# ENCODER0_REG_MTX register map
Vendor: Texas Instruments
Peripheral module from a debugger description file (folder J7ES).
Registers are 32-bit, access per field, reset 0x0 unless marked. A register's access mark holds for its fields unless they carry their own. Offsets are as the file gives them; lines under a group give offsets from that group; [hi:lo] are bit positions; {n}, {i} and the like mark numbered series; 'fields as' and 'values as' point back to an identical list; <NAME> marks a mode.

## ENCODER0_REG_MTX
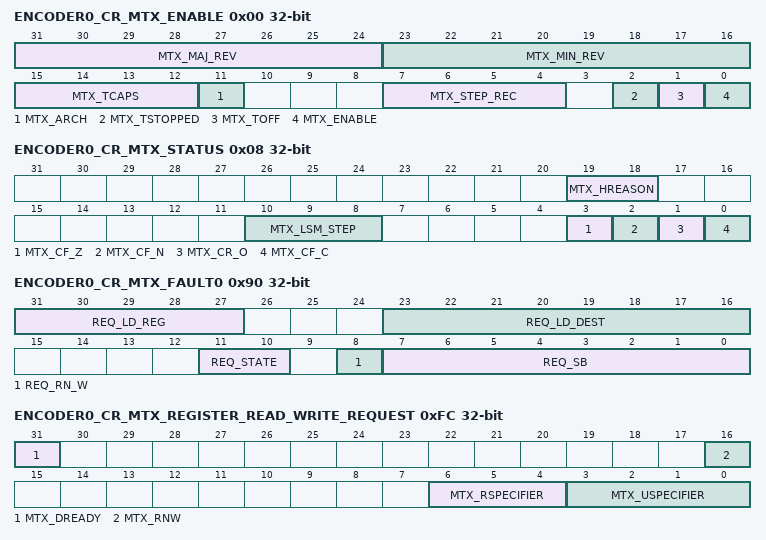
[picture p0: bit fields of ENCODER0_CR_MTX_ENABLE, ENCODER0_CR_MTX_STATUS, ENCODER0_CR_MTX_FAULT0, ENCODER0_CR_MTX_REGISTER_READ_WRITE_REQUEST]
0x00 ENCODER0_CR_MTX_ENABLE
  [31:24] MTX_MAJ_REV rw, [23:16] MTX_MIN_REV rw, [15:12] MTX_TCAPS rw, [11] MTX_ARCH rw, [7:4] MTX_STEP_REC rw, [2] MTX_TSTOPPED rw, [1] MTX_TOFF rw, [0] MTX_ENABLE rw
0x08 ENCODER0_CR_MTX_STATUS
  [19:18] MTX_HREASON rw, [10:8] MTX_LSM_STEP rw, [3] MTX_CF_Z rw, [2] MTX_CF_N rw, [1] MTX_CR_O rw, [0] MTX_CF_C rw
0x80 ENCODER0_CR_MTX_KICK
  [15:0] MTX_KICK rw
0x88 ENCODER0_CR_MTX_KICKI
  [15:0] MTX_KICKI rw
0x90 ENCODER0_CR_MTX_FAULT0
  [31:27] REQ_LD_REG rw, [23:16] REQ_LD_DEST rw, [11:10] REQ_STATE rw, [8] REQ_RN_W rw, [7:0] REQ_SB rw
0xF8 ENCODER0_CR_MTX_REGISTER_READ_WRITE_DATA rw
  [31:0] MTX_RWDATA
0xFC ENCODER0_CR_MTX_REGISTER_READ_WRITE_REQUEST
  [31] MTX_DREADY rw, [16] MTX_RNW rw, [6:4] MTX_RSPECIFIER rw, [3:0] MTX_USPECIFIER rw
0x100 ENCODER0_CR_MTX_RAM_ACCESS_DATA_EXCHANGE rw
  [31:0] MTX_MCMDATAX
0x104 ENCODER0_CR_MTX_RAM_ACCESS_DATA_TRANSFER rw
  [31:0] MTX_MCMDATAT
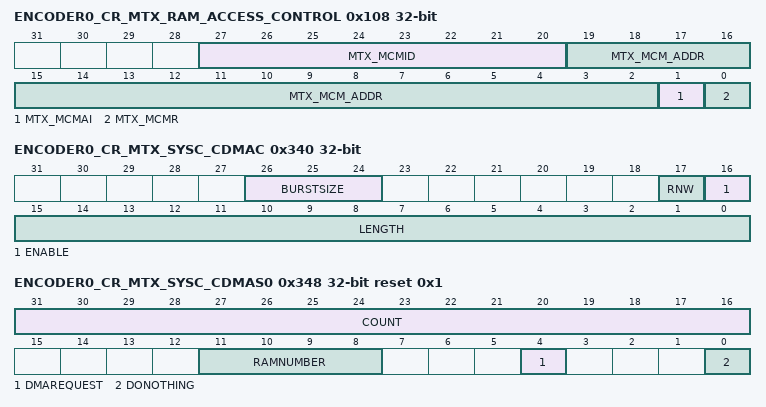
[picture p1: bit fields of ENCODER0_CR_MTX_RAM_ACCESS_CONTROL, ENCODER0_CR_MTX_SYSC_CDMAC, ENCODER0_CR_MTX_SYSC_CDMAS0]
0x108 ENCODER0_CR_MTX_RAM_ACCESS_CONTROL
  [27:20] MTX_MCMID rw, [19:2] MTX_MCM_ADDR rw, [1] MTX_MCMAI rw, [0] MTX_MCMR rw
0x10C ENCODER0_CR_MTX_RAM_ACCESS_STATUS
  [0] MTX_MTX_MCM_STAT rw
0x200 ENCODER0_CR_MTX_SOFT_RESET
  [0] MTX_RESET rw
0x340 ENCODER0_CR_MTX_SYSC_CDMAC
  [26:24] BURSTSIZE rw — This specifies the burst size used for DMA transfers.
  [17] RNW rw — This should be set to '0' to write to the core memories, or '1' to read from the core memories.
  [16] ENABLE rw — Causes a transfer to begin next time the transfer state machine is ready.
  [15:0] LENGTH rw — This specifies the transfer size of the DMA operation in terms of
0x344 ENCODER0_CR_MTX_SYSC_CDMAA
  [25:2] CDMAA_ADDRESS rw — This is the core DMA transfer start address.
0x348 ENCODER0_CR_MTX_SYSC_CDMAS0 ro reset 0x1
  [31:16] COUNT — This is the count of remaining items to be transferred.
  [11:8] RAMNUMBER — This indicates the current RAM number that a DMA transfer is targeting.
  [4] DMAREQUEST — This is a duplicate of the DMA request hardware line from this block to the DMA controller and may be needed if data transfer is from a host processor rather than the DMA controller.
  [0] DONOTHING — Transfer State == 'do_nothing'.
0x34C ENCODER0_CR_MTX_SYSC_CDMAS1 ro
  [25:2] CDMAS1_ADDRESS — This is the current core DMA transfer address.
0x350 ENCODER0_CR_MTX_SYSC_CDMAT rw
  [31:0] TRANSFERDATA — Data to be written to core RAMs [when writing only], or data read from core RAMs [when reading only].
